# psoc6_01 register map
Vendor: Cypress Semiconductor; Series: PSoC6_01; File version: 1.0
CPU: CM4 r0p1, little endian, MPU, FPU, VTOR, 3 interrupt priority bits
Registers are 32-bit, read-write, reset 0x0 unless marked. A register's access mark holds for its fields unless they carry their own. Offsets are from the block's base; [hi:lo] are bit positions; lines under a group give offsets from that group; {n}, {i} and the like mark numbered series.

## DW0 — Datawire Controller
Base 0x40280000
Same registers: DW1 0x40281000
0x00 CTL — Control
  [31] ENABLED — IP enable: '0': Disabled. Disabling the IP activates the IP's Active logic reset: Active logic and non-retention MMIO registers are reset (retention MMIO registers are not affected). '1': Enabled.
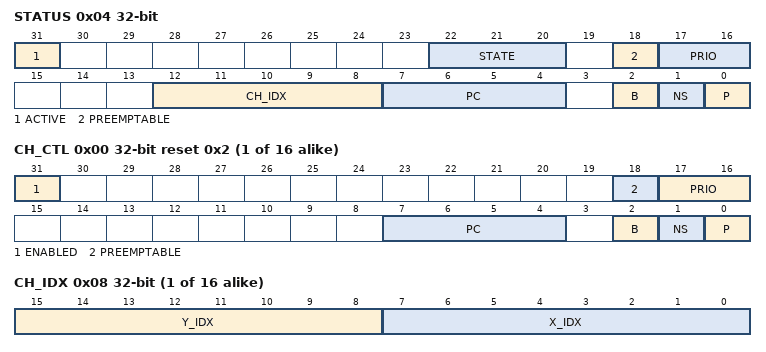
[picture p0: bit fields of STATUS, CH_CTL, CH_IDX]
0x04 STATUS ro (reset mask 0x80700000)
  [31] ACTIVE — Active channel present: '0': No. '1': Yes.
  [22:20] STATE — State of the DW controller. '0': Default/inactive state. '1': Loading descriptor. '2': Loading data element from source location. '3': Storing data element to destination location. '4': Update of active control information (e.g. source and destination addresses). '5': Wait for trigger de-activation.
  [18] PREEMPTABLE — Active channel preemptable.
  [17:16] PRIO — Active channel priority.
  [12:8] CH_IDX — Active channel index.
  [7:4] PC — Active channel protection context.
  [2] B — Active channel, non-bufferable/bufferable access control: '0': non-bufferable '1': bufferable.
  [1] NS — Active channel, secure/non-secure access control: '0': secure. '1': non-secure.
  [0] P — Active channel, user/privileged access control: '0': user mode. '1': privileged mode.
0x08 PENDING ro — Pending channels
  [31:0] CH_PENDING — Specifies pending DW channels; i.e. enabled channels whose trigger got activated. This field includes all channels that are in the pending state (not scheduled) or active state (scheduled and performing data transfer(s)).
0x10 STATUS_INTR ro — System interrupt control
  [31:0] CH — Reflects the INTR.CH bit fields of all channels.
0x14 STATUS_INTR_MASKED ro — Status of interrupts masked
  [31:0] CH — Reflects the INTR_MASKED.CH bit fields of all channels.
0x20 ACT_DESCR_CTL ro reset not defined — Active descriptor control
  [31:0] DATA — Copy of DESCR_CTL of the currently active descriptor.
0x24 ACT_DESCR_SRC ro reset not defined — Active descriptor source
  [31:0] DATA — Copy of DESCR_SRC of the currently active descriptor.
0x28 ACT_DESCR_DST ro reset not defined — Active descriptor destination
  [31:0] DATA — Copy of DESCR_DST of the currently active descriptor.
0x30 ACT_DESCR_X_CTL ro reset not defined — Active descriptor X loop control
  [31:0] DATA — Copy of DESCR_X_CTL of the currently active descriptor.
0x34 ACT_DESCR_Y_CTL ro reset not defined — Active descriptor Y loop control
  [31:0] DATA — Copy of DESCR_Y_CTL of the currently active descriptor.
0x38 ACT_DESCR_NEXT_PTR ro reset not defined — Active descriptor next pointer
  [31:2] ADDR — Copy of DESCR_NEXT_PTR of the currently active descriptor.
0x40 ACT_SRC ro reset not defined — Active source
  [31:0] SRC_ADDR — Current address of source location.
0x44 ACT_DST ro reset not defined — Active destination
  [31:0] DST_ADDR — Current address of destination location.
{0x800+0x20*i} CH_STRUCT[{i}] (i=0..15) group — DW channel structure
  0x00 CH_CTL reset 0x2 — Channel control
    [31] ENABLED — Channel enable: '0': Disabled. The channel's trigger is ignored and the channel cannot be made pending and therefore cannot be made active. If a pending channel is disabled, the channel is made non pending. If the activate channel is disabled, the channel is de-activated (bus transactions are completed). '1': Enabled. SW sets this field to '1' to enable a specific channel. HW sets this field to '0' on an error interrupt cause (the specific error is specified by CH_STATUS.INTR_CAUSE).
    [18] PREEMPTABLE — Specifies if the channel is preemptable. '0': Not preemptable. '1': Preemptable. This field allows higher priority pending channels (from a higher priority group; i.e. an active channel can NOT be preempted by a pending channel in the same priority group) to preempt the active channel in between 'single transfers' (a 1D transfer consists out of X_COUNT single transfers; a 2D transfer consists out of X_COUNT*Y_COUNT single transfers). Preemption will NOT affect the pending status of channel. As a result, after completion of a higher priority activated channel, the current channel may be reactivated.
    [17:16] PRIO — Channel priority: '0': highest priority. '1' '2' '3': lowest priority. Channels with the same priority constitute a priority group. Priority decoding determines the highest priority pending channel. This channel is determined as follows. First, the highest priority group with pending channels is identified. Second, within this priority group, round robin arbitration is applied. Round robin arbitration (within a priority group) gives the highest priority to the lower channel indices (within the priority group).
    [7:4] PC — Protection context. This field is set with the protection context of the transaction that writes this register; i.e. the 'write data' is ignored and instead the context is inherited from the write transaction (note the field attributes should be HW:RW, SW:R). All transactions for this channel uses the PC field for the protection context.
    [2] B — Non-bufferable/bufferable access control: '0': non-bufferable. '1': bufferable. This field is used to indicate to an AMBA bridge that a write transaction can complete without waiting for the destination to accept the write transaction data. All transactions for this channel uses the B field for the non-bufferable/bufferable access control ('hprot[2]').
    [1] NS — Secure/on-secure access control: '0': secure. '1': non-secure. This field is set with the secure/non-secure access control of the transaction that writes this register; i.e. the 'write data' is ignored and instead the access control is inherited from the write transaction (note the field attributes should be HW:RW, SW:R). All transactions for this channel use the NS field for the secure/non-secure access control ('hprot[4]').
    [0] P — User/privileged access control: '0': user mode. '1': privileged mode. This field is set with the user/privileged access control of the transaction that writes this register; i.e. the 'write data' is ignored and instead the access control is inherited from the write transaction (note the field attributes should be HW:RW, SW:R). All transactions for this channel use the P field for the user/privileged access control ('hprot[1]').
  0x04 CH_STATUS ro reset not defined — Channel status
    [3:0] INTR_CAUSE — Specifies the source of the interrupt cause: '0': NO_INTR '1': COMPLETION '2': SRC_BUS_ERROR '3': DST_BUS_ERROR '4': SRC_MISAL '5': DST_MISAL '6': CURR_PTR_NULL '7': ACTIVE_CH_DISABLED '8': DESCR_BUS_ERROR '9'-'15': Not used. For error related interrupt causes (INTR_CAUSE is '2', '3', ..., '8'), the channel is disabled (HW sets CH_CTL.ENABLED to '0').
  0x08 CH_IDX reset not defined — Channel current indices
    [15:8] Y_IDX — Specifies the Y loop index, with X_COUNT taken from the current descriptor. Note: HW sets this field to '0' when it updates the current descriptor pointer CH_CURR_PTR with DESCR_NEXT_PTR after execution of the current descriptor. Note: SW should set this field to '0' when it updates CH_CURR_PTR.
    [7:0] X_IDX — Specifies the X loop index. In the range of [0, X_COUNT], with X_COUNT taken from the current descriptor. Note: HW sets this field to '0' when it updates the current descriptor pointer CH_CURR_PTR with DESCR_NEXT_PTR after execution of the current descriptor. Note: SW should set this field to '0' when it updates CH_CURR_PTR.
  0x0C CH_CURR_PTR reset not defined — Channel current descriptor pointer
    [31:2] ADDR — Address of current descriptor. When this field is '0', there is no valid descriptor. Note: HW updates the current descriptor pointer CH_CURR_PTR with DESCR_NEXT_PTR after execution of the current descriptor. Note: Typically, when SW updates the current descriptor pointer CH_CURR_PTR, it also sets CH_IDX.X_IDX and CH_IDX.Y_IDX to '0'.
  0x10 INTR — Interrupt
    [0] CH — Set to '1', when event (as specified by CH_STATUS.INTR_CAUSE) is detected. Write INTR.CH field with '1', to clear bit. Write INTR_SET.CH field with '1', to set bit.
  0x14 INTR_SET — Interrupt set
    [0] CH — Write INTR_SET field with '1' to set corresponding INTR.CH field (a write of '0' has no effect).
  0x18 INTR_MASK — Interrupt mask
    [0] CH — Mask for corresponding field in INTR register.
  0x1C INTR_MASKED ro — Interrupt masked
    [0] CH — Logical and of corresponding INTR and INTR_MASK fields.

## Notices in the file
Copyright 2016-2019 Cypress Semiconductor Corporation
Licensed under the Apache License, Version 2.0 (the "License");
you may not use this file except in compliance with the License.
You may obtain a copy of the License at
http://www.apache.org/licenses/LICENSE-2.0
Unless required by applicable law or agreed to in writing, software
distributed under the License is distributed on an "AS IS" BASIS,
WITHOUT WARRANTIES OR CONDITIONS OF ANY KIND, either express or implied.
See the License for the specific language governing permissions and
limitations under the License.
